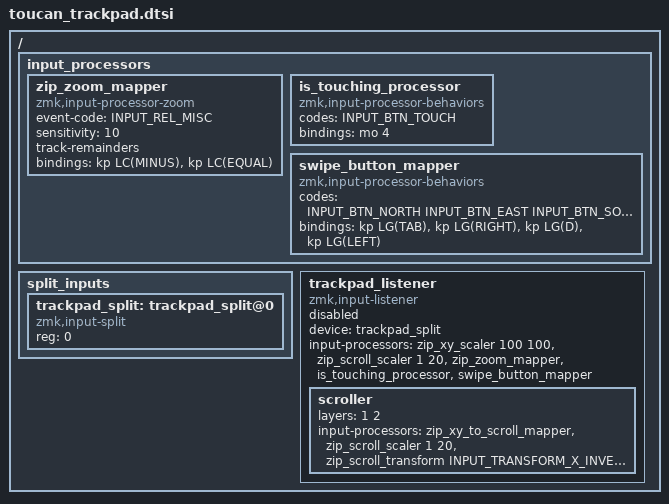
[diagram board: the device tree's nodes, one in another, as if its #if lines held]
/*
 * Shared Azoteq TPS43 trackpad wiring for the Toucan / Toucan36 shields.
 * Included from toucan.dtsi and toucan36.dtsi. Not a shield itself:
 * Zephyr shield discovery globs boards/shields/[shield]/Kconfig.shield, so a
 * loose .dtsi directly under boards/shields/ is invisible to it.
 *
 * Uncomment to build Windows/Linux gesture bindings instead of macOS.
 */
// #define TOUCAN_WIN_MODE

#include <input/processors.dtsi>
#include <dt-bindings/input/input-event-codes.h>
#include <dt-bindings/zmk/input_transform.h>
#include <dt-bindings/zmk/keys.h>

/ {
    input_processors {
        zip_zoom_mapper: zip_zoom_mapper {
            compatible = "zmk,input-processor-zoom";
            #input-processor-cells = <0>;
            event-code = <INPUT_REL_MISC>;
            sensitivity = <10>;
            track-remainders;
#ifdef TOUCAN_WIN_MODE
            bindings = <&kp LC(MINUS)>, <&kp LC(EQUAL)>;
#else
            bindings = <&kp LG(MINUS)>, <&kp LG(EQUAL)>;
#endif
        };

        // Any finger on the pad momentarily activates the MOUSE layer (index 4).
        // Literal 4 here — this file is included before the keymap's #define MOUSE exists.
        // MOUSE must stay at index 4 in every keymap that includes this file.
        is_touching_processor: is_touching_processor {
            compatible = "zmk,input-processor-behaviors";
            #input-processor-cells = <0>;
            codes = <INPUT_BTN_TOUCH>;
            bindings = <&mo 4>;
        };

        swipe_button_mapper: swipe_button_mapper {
            compatible = "zmk,input-processor-behaviors";
            #input-processor-cells = <0>;
            codes = <INPUT_BTN_NORTH INPUT_BTN_EAST INPUT_BTN_SOUTH INPUT_BTN_WEST>;
#ifdef TOUCAN_WIN_MODE
            bindings = <&kp LG(TAB)>, <&kp LG(RIGHT)>, <&kp LG(D)>, <&kp LG(LEFT)>;
#else
            bindings = <&kp LC(LG(UP))>, <&kp LC(LG(RIGHT))>,
                       <&kp LC(LG(DOWN))>, <&kp LC(LG(LEFT))>;
#endif
        };
    };

    split_inputs {
        #address-cells = <1>;
        #size-cells = <0>;

        trackpad_split: trackpad_split@0 {
            compatible = "zmk,input-split";
            reg = <0>;
        };
    };

    trackpad_listener: trackpad_listener {
        compatible = "zmk,input-listener";
        status = "disabled";           // enabled on the left (central) half only
        device = <&trackpad_split>;
        input-processors = <&zip_xy_scaler 100 100>, <&zip_scroll_scaler 1 20>,
                           <&zip_zoom_mapper>, <&is_touching_processor>,
                           <&swipe_button_mapper>;
        scroller {
            layers = <1 2>;             // NAV, NUM
            input-processors = <
                &zip_xy_to_scroll_mapper
                &zip_scroll_scaler 1 20
                &zip_scroll_transform INPUT_TRANSFORM_X_INVERT
            >;
        };
    };
};
